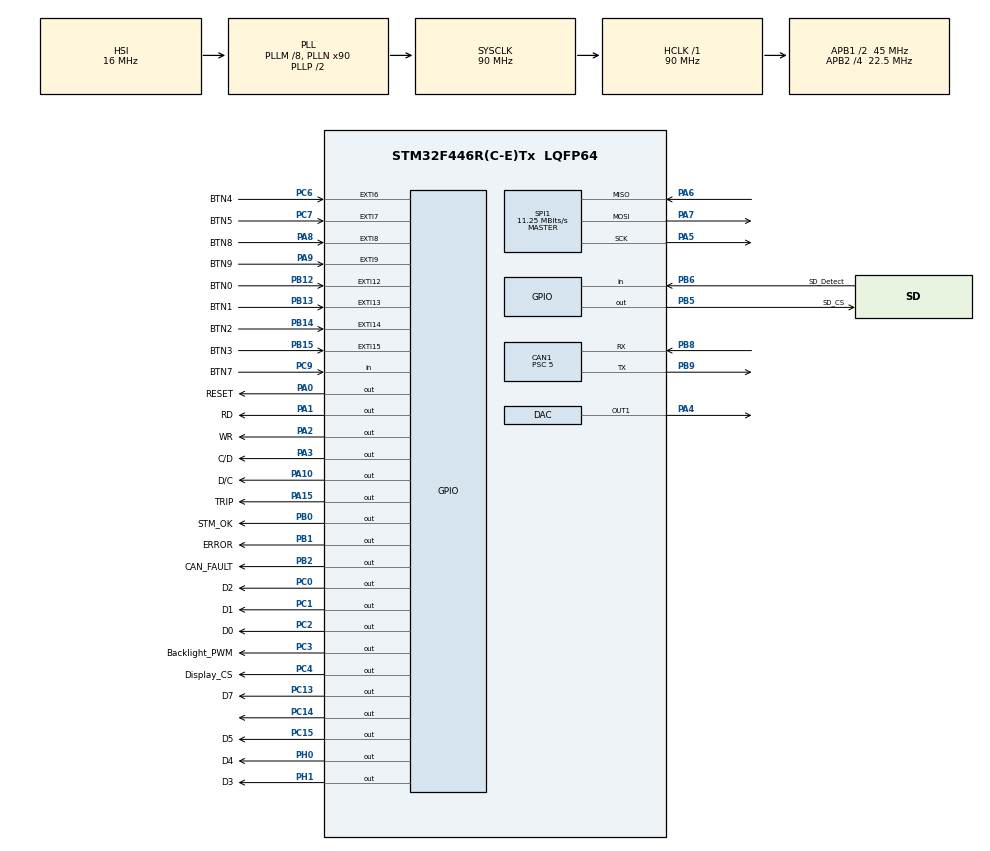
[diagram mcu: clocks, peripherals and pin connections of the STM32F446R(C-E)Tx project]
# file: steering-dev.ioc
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CAN1.BS1=CAN_BS1_15TQ
CAN1.BS2=CAN_BS2_2TQ
CAN1.CalculateBaudRate=500000
CAN1.CalculateTimeBit=2000
CAN1.CalculateTimeQuantum=111.11111111111111
CAN1.Mode=CAN_MODE_LOOPBACK
CAN1.Prescaler=5
CAN1.SJW=CAN_SJW_1TQ
DAC.DAC_Trigger=DAC_TRIGGER_T2_TRGO
Dma.DAC1.0.Direction=DMA_MEMORY_TO_PERIPH
Dma.DAC1.0.FIFOMode=DMA_FIFOMODE_DISABLE
Dma.DAC1.0.Instance=DMA1_Stream5
Dma.DAC1.0.MemDataAlignment=DMA_MDATAALIGN_WORD
Dma.DAC1.0.MemInc=DMA_MINC_ENABLE
Dma.DAC1.0.Mode=DMA_CIRCULAR
Dma.DAC1.0.PeriphDataAlignment=DMA_PDATAALIGN_WORD
Dma.DAC1.0.PeriphInc=DMA_PINC_DISABLE
Dma.DAC1.0.Priority=DMA_PRIORITY_LOW
Dma.Request0=DAC1
FATFS._FS_REENTRANT=0
FATFS._MAX_SS=4096
FREERTOS.Tasks01=defaultTask,24,128,StartDefaultTask,Default,NULL,Dynamic,NULL,NULL
FREERTOS.configTOTAL_HEAP_SIZE=3072
IWDG.Prescaler=IWDG_PRESCALER_128
IWDG.Reload=1023
Mcu.Family=STM32F4
Mcu.Name=STM32F446R(C-E)Tx
Mcu.Package=LQFP64
NVIC.CAN1_RX0_IRQn=true\:5\:0\:false\:false\:true\:true\:true\:true\:true
NVIC.CAN1_RX1_IRQn=true\:5\:0\:false\:false\:true\:true\:true\:true\:true
NVIC.DMA1_Stream5_IRQn=true\:5\:0\:false\:false\:true\:true\:false\:true\:true
NVIC.EXTI15_10_IRQn=true\:5\:0\:false\:false\:true\:true\:true\:true\:true
NVIC.EXTI9_5_IRQn=true\:5\:0\:false\:false\:true\:true\:true\:true\:true
NVIC.PriorityGroup=NVIC_PRIORITYGROUP_4
NVIC.TIM3_IRQn=true\:5\:0\:false\:false\:true\:true\:true\:true\:true
NVIC.TIM8_TRG_COM_TIM14_IRQn=true\:15\:0\:false\:false\:true\:false\:false\:true\:true
NVIC.TimeBase=TIM8_TRG_COM_TIM14_IRQn
NVIC.TimeBaseIP=TIM14
PA0-WKUP.GPIO_Label=RESET
PA0-WKUP.Signal=GPIO_Output
PA1.GPIO_Label=RD
PA1.Signal=GPIO_Output
PA10.GPIO_Label=D/C
PA10.GPIO_PuPd=GPIO_PULLUP
PA10.Signal=GPIO_Output
PA13.Mode=Serial_Wire
PA13.Signal=SYS_JTMS-SWDIO
PA14.Mode=Serial_Wire
PA14.Signal=SYS_JTCK-SWCLK
PA15.GPIO_Label=TRIP
PA15.GPIO_PuPd=GPIO_PULLDOWN
PA15.Signal=GPIO_Output
PA2.GPIO_Label=WR
PA2.Signal=GPIO_Output
PA3.GPIO_Label=C/D
PA3.Signal=GPIO_Output
PA4.Signal=COMP_DAC1_group
PA5.Mode=Full_Duplex_Master
PA5.Signal=SPI1_SCK
PA6.Mode=Full_Duplex_Master
PA6.Signal=SPI1_MISO
PA7.Mode=Full_Duplex_Master
PA7.Signal=SPI1_MOSI
PA8.GPIO_Label=BTN8
PA8.GPIO_ModeDefaultEXTI=GPIO_MODE_IT_FALLING
PA8.GPIO_PuPd=GPIO_PULLUP
PA8.Signal=GPXTI8
PA9.GPIO_Label=BTN9
PA9.GPIO_ModeDefaultEXTI=GPIO_MODE_IT_FALLING
PA9.GPIO_PuPd=GPIO_PULLUP
PA9.Signal=GPXTI9
PB0.GPIO_Label=STM_OK
PB0.Signal=GPIO_Output
PB1.GPIO_Label=ERROR
PB1.Signal=GPIO_Output
PB12.GPIO_Label=BTN0
PB12.GPIO_ModeDefaultEXTI=GPIO_MODE_IT_FALLING
PB12.GPIO_PuPd=GPIO_PULLUP
PB12.Signal=GPXTI12
PB13.GPIO_Label=BTN1
PB13.GPIO_ModeDefaultEXTI=GPIO_MODE_IT_FALLING
PB13.GPIO_PuPd=GPIO_PULLUP
PB13.Signal=GPXTI13
PB14.GPIO_Label=BTN2
PB14.GPIO_ModeDefaultEXTI=GPIO_MODE_IT_FALLING
PB14.GPIO_PuPd=GPIO_PULLUP
PB14.Signal=GPXTI14
PB15.GPIO_Label=BTN3
PB15.GPIO_ModeDefaultEXTI=GPIO_MODE_IT_FALLING
PB15.GPIO_PuPd=GPIO_PULLUP
PB15.Signal=GPXTI15
PB2.GPIO_Label=CAN_FAULT
PB2.Signal=GPIO_Output
PB5.GPIO_Label=SD_CS
PB5.Signal=GPIO_Output
PB6.GPIO_Label=SD_Detect
PB6.Signal=GPIO_Input
PB8.Mode=CAN_Activate
PB8.Signal=CAN1_RX
PB9.Mode=CAN_Activate
PB9.Signal=CAN1_TX
PC0.GPIO_Label=D2
PC0.Signal=GPIO_Output
PC1.GPIO_Label=D1
PC1.Signal=GPIO_Output
PC13.GPIO_Label=D7
PC13.Signal=GPIO_Output
PC14-OSC32_IN.Signal=GPIO_Output
PC15-OSC32_OUT.GPIO_Label=D5
PC15-OSC32_OUT.Signal=GPIO_Output
PC2.GPIO_Label=D0
PC2.Signal=GPIO_Output
PC3.GPIO_Label=Backlight_PWM
PC3.Signal=GPIO_Output
PC4.GPIO_Label=Display_CS
PC4.Signal=GPIO_Output
PC6.GPIO_Label=BTN4
PC6.GPIO_ModeDefaultEXTI=GPIO_MODE_IT_FALLING
PC6.GPIO_PuPd=GPIO_PULLUP
PC6.Signal=GPXTI6
PC7.GPIO_Label=BTN5
PC7.GPIO_ModeDefaultEXTI=GPIO_MODE_IT_FALLING
PC7.GPIO_PuPd=GPIO_PULLUP
PC7.Signal=GPXTI7
PC9.GPIO_Label=BTN7
PC9.GPIO_PuPd=GPIO_PULLUP
PC9.Signal=GPIO_Input
PH0-OSC_IN.GPIO_Label=D4
PH0-OSC_IN.Signal=GPIO_Output
PH1-OSC_OUT.GPIO_Label=D3
PH1-OSC_OUT.Signal=GPIO_Output
ProjectManager.HeapSize=0x200
ProjectManager.StackSize=0x400
ProjectManager.TargetToolchain=Makefile
RCC.AHBFreq_Value=90000000
RCC.APB1CLKDivider=RCC_HCLK_DIV2
RCC.APB1Freq_Value=45000000
RCC.APB1TimFreq_Value=90000000
RCC.APB2CLKDivider=RCC_HCLK_DIV4
RCC.APB2Freq_Value=22500000
RCC.APB2TimFreq_Value=45000000
RCC.CortexFreq_Value=90000000
RCC.HCLKFreq_Value=90000000
RCC.PLLM=8
RCC.PLLN=90
RCC.PLLQ=6
RCC.PLLSAIP=RCC_PLLSAIP_DIV4
RCC.PLLSourceVirtual=RCC_PLLSOURCE_HSI
RCC.SYSCLKFreq_VALUE=90000000
RCC.SYSCLKSource=RCC_SYSCLKSOURCE_PLLCLK
RCC.USBCLockSelection=RCC_CLK48CLKSOURCE_PLLSAIP
RCC.USBFreq_Value=48000000
RCC.VCOOutputFreq_Value=180000000
SH.COMP_DAC1_group.0=DAC_OUT1,DAC_OUT1
SPI1.BaudRatePrescaler=SPI_BAUDRATEPRESCALER_2
SPI1.CalculateBaudRate=11.25 MBits/s
SPI1.Direction=SPI_DIRECTION_2LINES
SPI1.Mode=SPI_MODE_MASTER
SPI1.VirtualType=VM_MASTER
TIM2.AutoReloadPreload=TIM_AUTORELOAD_PRELOAD_DISABLE
TIM2.Period=100
TIM2.Prescaler=31
TIM2.TIM_MasterOutputTrigger=TIM_TRGO_UPDATE
TIM2.TIM_MasterSlaveMode=TIM_MASTERSLAVEMODE_DISABLE
TIM3.Period=275
TIM3.Prescaler=4095
VP_FATFS_VS_Generic.Mode=User_defined
VP_FREERTOS_VS_CMSIS_V2.Mode=CMSIS_V2
VP_IWDG_VS_IWDG.Mode=IWDG_Activate
VP_SYS_VS_tim14.Mode=TIM14
VP_TIM2_VS_ClockSourceINT.Mode=Internal
VP_TIM3_VS_ClockSourceINT.Mode=Internal
board=custom

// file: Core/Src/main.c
/* USER CODE BEGIN Header */
/**
  ******************************************************************************
  * @file           : main.c
  * @brief          : Main program body
  ******************************************************************************
  * @attention
  *
  * Copyright (c) 2023 STMicroelectronics.
  * All rights reserved.
  *
  * This software is licensed under terms that can be found in the LICENSE file
  * in the root directory of this software component.
  * If no LICENSE file comes with this software, it is provided AS-IS.
  *
  ******************************************************************************
  */
/* USER CODE END Header */
#include "main.h"
#include "cmsis_os.h"
#include "fatfs.h"

CAN_HandleTypeDef hcan1;

DAC_HandleTypeDef hdac;
DMA_HandleTypeDef hdma_dac1;

IWDG_HandleTypeDef hiwdg;

SPI_HandleTypeDef hspi1;

TIM_HandleTypeDef htim2;
TIM_HandleTypeDef htim3;

/* Definitions for defaultTask */
osThreadId_t defaultTaskHandle;
const osThreadAttr_t defaultTask_attributes = {
  .name = "defaultTask",
  .stack_size = 128 * 4,
  .priority = (osPriority_t) osPriorityNormal,
};

void SystemClock_Config(void);
static void MX_GPIO_Init(void);
static void MX_DMA_Init(void);
static void MX_CAN1_Init(void);
static void MX_SPI1_Init(void);
static void MX_TIM2_Init(void);
static void MX_DAC_Init(void);
static void MX_TIM3_Init(void);
static void MX_IWDG_Init(void);
void StartDefaultTask(void *argument);

/* USER CODE BEGIN PFP */
void CPP_UserSetup(void);
/* USER CODE END PFP */

int main(void)
{

  /* MCU Configuration--------------------------------------------------------*/

  /* Reset of all peripherals, Initializes the Flash interface and the Systick. */
  HAL_Init();

  /* Configure the system clock */
  SystemClock_Config();

  /* USER CODE BEGIN SysInit */
   HAL_NVIC_SetPriority(TIM1_TRG_COM_TIM11_IRQn, 1U, 0U);
  __enable_irq();
  __set_BASEPRI(6);
  /* USER CODE END SysInit */

  /* Initialize all configured peripherals */
  MX_GPIO_Init();
  MX_DMA_Init();
  MX_CAN1_Init();
  MX_SPI1_Init();
  MX_FATFS_Init();
  MX_TIM2_Init();
  MX_DAC_Init();
  MX_TIM3_Init();
  MX_IWDG_Init();
  /* USER CODE BEGIN 2 */

//  HAL_DAC_Start(&hdac, DAC_CHANNEL_1);
//  HAL_DAC_Start_DMA(&hdac, DAC_CHANNEL_1, sine_vals, 100, DAC_ALIGN_12B_R);

  HAL_NVIC_SetPriority(TIM1_TRG_COM_TIM11_IRQn, 15U, 0U);
  /* USER CODE END 2 */

  /* Init scheduler */
  CPP_UserSetup();

  /* Create the thread(s) */
  /* creation of defaultTask */
  defaultTaskHandle = osThreadNew(StartDefaultTask, NULL, &defaultTask_attributes);

  /* Start scheduler */
  osKernelStart();

  /* We should never get here as control is now taken by the scheduler */

  /* Infinite loop */
  /* USER CODE BEGIN WHILE */

  while (1)
  {
	HAL_GPIO_TogglePin(STM_OK_GPIO_Port, STM_OK_Pin);
	HAL_Delay(500);

    /* USER CODE END WHILE */

  }
}

void SystemClock_Config(void)
{
  RCC_OscInitTypeDef RCC_OscInitStruct = {0};
  RCC_ClkInitTypeDef RCC_ClkInitStruct = {0};

  /** Configure the main internal regulator output voltage
  */
  __HAL_RCC_PWR_CLK_ENABLE();
  __HAL_PWR_VOLTAGESCALING_CONFIG(PWR_REGULATOR_VOLTAGE_SCALE3);

  /** Initializes the RCC Oscillators according to the specified parameters
  * in the RCC_OscInitTypeDef structure.
  */
  RCC_OscInitStruct.OscillatorType = RCC_OSCILLATORTYPE_HSI|RCC_OSCILLATORTYPE_LSI;
  RCC_OscInitStruct.HSIState = RCC_HSI_ON;
  RCC_OscInitStruct.HSICalibrationValue = RCC_HSICALIBRATION_DEFAULT;
  RCC_OscInitStruct.LSIState = RCC_LSI_ON;
  RCC_OscInitStruct.PLL.PLLState = RCC_PLL_ON;
  RCC_OscInitStruct.PLL.PLLSource = RCC_PLLSOURCE_HSI;
  RCC_OscInitStruct.PLL.PLLM = 8;
  RCC_OscInitStruct.PLL.PLLN = 90;
  RCC_OscInitStruct.PLL.PLLP = RCC_PLLP_DIV2;
  RCC_OscInitStruct.PLL.PLLQ = 6;
  RCC_OscInitStruct.PLL.PLLR = 2;
  if (HAL_RCC_OscConfig(&RCC_OscInitStruct) != HAL_OK)
  {
    Error_Handler();
  }

  /** Initializes the CPU, AHB and APB buses clocks
  */
  RCC_ClkInitStruct.ClockType = RCC_CLOCKTYPE_HCLK|RCC_CLOCKTYPE_SYSCLK
                              |RCC_CLOCKTYPE_PCLK1|RCC_CLOCKTYPE_PCLK2;
  RCC_ClkInitStruct.SYSCLKSource = RCC_SYSCLKSOURCE_PLLCLK;
  RCC_ClkInitStruct.AHBCLKDivider = RCC_SYSCLK_DIV1;
  RCC_ClkInitStruct.APB1CLKDivider = RCC_HCLK_DIV2;
  RCC_ClkInitStruct.APB2CLKDivider = RCC_HCLK_DIV4;

  if (HAL_RCC_ClockConfig(&RCC_ClkInitStruct, FLASH_LATENCY_2) != HAL_OK)
  {
    Error_Handler();
  }
}

static void MX_CAN1_Init(void)
{

  hcan1.Instance = CAN1;
  hcan1.Init.Prescaler = 5;
  hcan1.Init.Mode = CAN_MODE_LOOPBACK;
  hcan1.Init.SyncJumpWidth = CAN_SJW_1TQ;
  hcan1.Init.TimeSeg1 = CAN_BS1_15TQ;
  hcan1.Init.TimeSeg2 = CAN_BS2_2TQ;
  hcan1.Init.TimeTriggeredMode = DISABLE;
  hcan1.Init.AutoBusOff = DISABLE;
  hcan1.Init.AutoWakeUp = DISABLE;
  hcan1.Init.AutoRetransmission = DISABLE;
  hcan1.Init.ReceiveFifoLocked = DISABLE;
  hcan1.Init.TransmitFifoPriority = DISABLE;
  if (HAL_CAN_Init(&hcan1) != HAL_OK)
  {
    Error_Handler();
  }

}

static void MX_DAC_Init(void)
{

  DAC_ChannelConfTypeDef sConfig = {0};

  /** DAC Initialization
  */
  hdac.Instance = DAC;
  if (HAL_DAC_Init(&hdac) != HAL_OK)
  {
    Error_Handler();
  }

  /** DAC channel OUT1 config
  */
  sConfig.DAC_Trigger = DAC_TRIGGER_T2_TRGO;
  sConfig.DAC_OutputBuffer = DAC_OUTPUTBUFFER_ENABLE;
  if (HAL_DAC_ConfigChannel(&hdac, &sConfig, DAC_CHANNEL_1) != HAL_OK)
  {
    Error_Handler();
  }

}

static void MX_IWDG_Init(void)
{

  hiwdg.Instance = IWDG;
  hiwdg.Init.Prescaler = IWDG_PRESCALER_128;
  hiwdg.Init.Reload = 1023;
  if (HAL_IWDG_Init(&hiwdg) != HAL_OK)
  {
    Error_Handler();
  }

}

static void MX_SPI1_Init(void)
{

  /* SPI1 parameter configuration*/
  hspi1.Instance = SPI1;
  hspi1.Init.Mode = SPI_MODE_MASTER;
  hspi1.Init.Direction = SPI_DIRECTION_2LINES;
  hspi1.Init.DataSize = SPI_DATASIZE_8BIT;
  hspi1.Init.CLKPolarity = SPI_POLARITY_LOW;
  hspi1.Init.CLKPhase = SPI_PHASE_1EDGE;
  hspi1.Init.NSS = SPI_NSS_SOFT;
  hspi1.Init.BaudRatePrescaler = SPI_BAUDRATEPRESCALER_2;
  hspi1.Init.FirstBit = SPI_FIRSTBIT_MSB;
  hspi1.Init.TIMode = SPI_TIMODE_DISABLE;
  hspi1.Init.CRCCalculation = SPI_CRCCALCULATION_DISABLE;
  hspi1.Init.CRCPolynomial = 10;
  if (HAL_SPI_Init(&hspi1) != HAL_OK)
  {
    Error_Handler();
  }

}

static void MX_TIM2_Init(void)
{

  TIM_ClockConfigTypeDef sClockSourceConfig = {0};
  TIM_MasterConfigTypeDef sMasterConfig = {0};

  htim2.Instance = TIM2;
  htim2.Init.Prescaler = 31;
  htim2.Init.CounterMode = TIM_COUNTERMODE_UP;
  htim2.Init.Period = 100;
  htim2.Init.ClockDivision = TIM_CLOCKDIVISION_DIV1;
  htim2.Init.AutoReloadPreload = TIM_AUTORELOAD_PRELOAD_DISABLE;
  if (HAL_TIM_Base_Init(&htim2) != HAL_OK)
  {
    Error_Handler();
  }
  sClockSourceConfig.ClockSource = TIM_CLOCKSOURCE_INTERNAL;
  if (HAL_TIM_ConfigClockSource(&htim2, &sClockSourceConfig) != HAL_OK)
  {
    Error_Handler();
  }
  sMasterConfig.MasterOutputTrigger = TIM_TRGO_UPDATE;
  sMasterConfig.MasterSlaveMode = TIM_MASTERSLAVEMODE_DISABLE;
  if (HAL_TIMEx_MasterConfigSynchronization(&htim2, &sMasterConfig) != HAL_OK)
  {
    Error_Handler();
  }

}

static void MX_TIM3_Init(void)
{

  TIM_ClockConfigTypeDef sClockSourceConfig = {0};
  TIM_MasterConfigTypeDef sMasterConfig = {0};

  htim3.Instance = TIM3;
  htim3.Init.Prescaler = 4095;
  htim3.Init.CounterMode = TIM_COUNTERMODE_UP;
  htim3.Init.Period = 275;
  htim3.Init.ClockDivision = TIM_CLOCKDIVISION_DIV1;
  htim3.Init.AutoReloadPreload = TIM_AUTORELOAD_PRELOAD_DISABLE;
  if (HAL_TIM_Base_Init(&htim3) != HAL_OK)
  {
    Error_Handler();
  }
  sClockSourceConfig.ClockSource = TIM_CLOCKSOURCE_INTERNAL;
  if (HAL_TIM_ConfigClockSource(&htim3, &sClockSourceConfig) != HAL_OK)
  {
    Error_Handler();
  }
  sMasterConfig.MasterOutputTrigger = TIM_TRGO_RESET;
  sMasterConfig.MasterSlaveMode = TIM_MASTERSLAVEMODE_DISABLE;
  if (HAL_TIMEx_MasterConfigSynchronization(&htim3, &sMasterConfig) != HAL_OK)
  {
    Error_Handler();
  }

}

static void MX_DMA_Init(void)
{

  /* DMA controller clock enable */
  __HAL_RCC_DMA1_CLK_ENABLE();

  /* DMA interrupt init */
  /* DMA1_Stream5_IRQn interrupt configuration */
  HAL_NVIC_SetPriority(DMA1_Stream5_IRQn, 5, 0);
  HAL_NVIC_EnableIRQ(DMA1_Stream5_IRQn);

}

static void MX_GPIO_Init(void)
{
  GPIO_InitTypeDef GPIO_InitStruct = {0};

  /* GPIO Ports Clock Enable */
  __HAL_RCC_GPIOC_CLK_ENABLE();
  __HAL_RCC_GPIOH_CLK_ENABLE();
  __HAL_RCC_GPIOA_CLK_ENABLE();
  __HAL_RCC_GPIOB_CLK_ENABLE();

  /*Configure GPIO pin Output Level */
  HAL_GPIO_WritePin(GPIOC, D7_Pin|GPIO_PIN_14|D5_Pin|D2_Pin
                          |D1_Pin|D0_Pin|Backlight_PWM_Pin|Display_CS_Pin, GPIO_PIN_RESET);

  /*Configure GPIO pin Output Level */
  HAL_GPIO_WritePin(GPIOH, D4_Pin|D3_Pin, GPIO_PIN_RESET);

  /*Configure GPIO pin Output Level */
  HAL_GPIO_WritePin(GPIOA, RESET_Pin|RD_Pin|WR_Pin|C_D_Pin
                          |D_C_Pin|TRIP_Pin, GPIO_PIN_RESET);

  /*Configure GPIO pin Output Level */
  HAL_GPIO_WritePin(GPIOB, STM_OK_Pin|ERROR_Pin|CAN_FAULT_Pin|SD_CS_Pin, GPIO_PIN_RESET);

  /*Configure GPIO pins : D7_Pin PC14 D5_Pin D2_Pin
                           D1_Pin D0_Pin Backlight_PWM_Pin Display_CS_Pin */
  GPIO_InitStruct.Pin = D7_Pin|GPIO_PIN_14|D5_Pin|D2_Pin
                          |D1_Pin|D0_Pin|Backlight_PWM_Pin|Display_CS_Pin;
  GPIO_InitStruct.Mode = GPIO_MODE_OUTPUT_PP;
  GPIO_InitStruct.Pull = GPIO_NOPULL;
  GPIO_InitStruct.Speed = GPIO_SPEED_FREQ_LOW;
  HAL_GPIO_Init(GPIOC, &GPIO_InitStruct);

  /*Configure GPIO pins : D4_Pin D3_Pin */
  GPIO_InitStruct.Pin = D4_Pin|D3_Pin;
  GPIO_InitStruct.Mode = GPIO_MODE_OUTPUT_PP;
  GPIO_InitStruct.Pull = GPIO_NOPULL;
  GPIO_InitStruct.Speed = GPIO_SPEED_FREQ_LOW;
  HAL_GPIO_Init(GPIOH, &GPIO_InitStruct);

  /*Configure GPIO pins : RESET_Pin RD_Pin WR_Pin C_D_Pin */
  GPIO_InitStruct.Pin = RESET_Pin|RD_Pin|WR_Pin|C_D_Pin;
  GPIO_InitStruct.Mode = GPIO_MODE_OUTPUT_PP;
  GPIO_InitStruct.Pull = GPIO_NOPULL;
  GPIO_InitStruct.Speed = GPIO_SPEED_FREQ_LOW;
  HAL_GPIO_Init(GPIOA, &GPIO_InitStruct);

  /*Configure GPIO pins : STM_OK_Pin ERROR_Pin CAN_FAULT_Pin SD_CS_Pin */
  GPIO_InitStruct.Pin = STM_OK_Pin|ERROR_Pin|CAN_FAULT_Pin|SD_CS_Pin;
  GPIO_InitStruct.Mode = GPIO_MODE_OUTPUT_PP;
  GPIO_InitStruct.Pull = GPIO_NOPULL;
  GPIO_InitStruct.Speed = GPIO_SPEED_FREQ_LOW;
  HAL_GPIO_Init(GPIOB, &GPIO_InitStruct);

  /*Configure GPIO pins : BTN0_Pin BTN2_Pin BTN3_Pin */
  GPIO_InitStruct.Pin = BTN0_Pin|BTN2_Pin|BTN3_Pin;
  GPIO_InitStruct.Mode = GPIO_MODE_IT_FALLING;
  GPIO_InitStruct.Pull = GPIO_PULLUP;
  HAL_GPIO_Init(GPIOB, &GPIO_InitStruct);

  /*Configure GPIO pin : BTN1_Pin */
  GPIO_InitStruct.Pin = BTN1_Pin;
  GPIO_InitStruct.Mode = GPIO_MODE_IT_RISING;
  GPIO_InitStruct.Pull = GPIO_PULLUP;
  HAL_GPIO_Init(BTN1_GPIO_Port, &GPIO_InitStruct);

  /*Configure GPIO pins : BTN4_Pin BTN5_Pin BTN6_Pin */
  GPIO_InitStruct.Pin = BTN4_Pin|BTN5_Pin|BTN6_Pin;
  GPIO_InitStruct.Mode = GPIO_MODE_IT_FALLING;
  GPIO_InitStruct.Pull = GPIO_PULLUP;
  HAL_GPIO_Init(GPIOC, &GPIO_InitStruct);

  /*Configure GPIO pin : BTN7_Pin */
  GPIO_InitStruct.Pin = BTN7_Pin;
  GPIO_InitStruct.Mode = GPIO_MODE_INPUT;
  GPIO_InitStruct.Pull = GPIO_PULLUP;
  HAL_GPIO_Init(BTN7_GPIO_Port, &GPIO_InitStruct);

  /*Configure GPIO pin : BTN8_Pin */
  GPIO_InitStruct.Pin = BTN8_Pin;
  GPIO_InitStruct.Mode = GPIO_MODE_INPUT;
  GPIO_InitStruct.Pull = GPIO_PULLUP;
  HAL_GPIO_Init(BTN8_GPIO_Port, &GPIO_InitStruct);

  /*Configure GPIO pin : BTN9_Pin */
  GPIO_InitStruct.Pin = BTN9_Pin;
  GPIO_InitStruct.Mode = GPIO_MODE_IT_FALLING;
  GPIO_InitStruct.Pull = GPIO_PULLUP;
  HAL_GPIO_Init(BTN9_GPIO_Port, &GPIO_InitStruct);

  /*Configure GPIO pin : D_C_Pin */
  GPIO_InitStruct.Pin = D_C_Pin;
  GPIO_InitStruct.Mode = GPIO_MODE_OUTPUT_PP;
  GPIO_InitStruct.Pull = GPIO_PULLUP;
  GPIO_InitStruct.Speed = GPIO_SPEED_FREQ_LOW;
  HAL_GPIO_Init(D_C_GPIO_Port, &GPIO_InitStruct);

  /*Configure GPIO pin : TRIP_Pin */
  GPIO_InitStruct.Pin = TRIP_Pin;
  GPIO_InitStruct.Mode = GPIO_MODE_OUTPUT_PP;
  GPIO_InitStruct.Pull = GPIO_PULLDOWN;
  GPIO_InitStruct.Speed = GPIO_SPEED_FREQ_LOW;
  HAL_GPIO_Init(TRIP_GPIO_Port, &GPIO_InitStruct);

  /*Configure GPIO pin : SD_Detect_Pin */
  GPIO_InitStruct.Pin = SD_Detect_Pin;
  GPIO_InitStruct.Mode = GPIO_MODE_INPUT;
  GPIO_InitStruct.Pull = GPIO_NOPULL;
  HAL_GPIO_Init(SD_Detect_GPIO_Port, &GPIO_InitStruct);

  /* EXTI interrupt init*/
  HAL_NVIC_SetPriority(EXTI9_5_IRQn, 5, 0);
  HAL_NVIC_EnableIRQ(EXTI9_5_IRQn);

  HAL_NVIC_SetPriority(EXTI15_10_IRQn, 5, 0);
  HAL_NVIC_EnableIRQ(EXTI15_10_IRQn);

}

void StartDefaultTask(void *argument)
{
  /* USER CODE BEGIN 5 */
//   /* Infinite loop */
//   for(;;)
//   {
// 	HAL_GPIO_TogglePin(STM_OK_GPIO_Port, STM_OK_Pin);
// 	// HAL_GPIO_TogglePin(DAC_OUT1_GPIO_Port, DAC_OUT1_Pin);
// 	osDelay(500);
//   }
  /* USER CODE END 5 */
}

void HAL_TIM_PeriodElapsedCallback(TIM_HandleTypeDef *htim)
{
  if (htim->Instance == TIM14) {
    HAL_IncTick();
  }
}

void Error_Handler(void)
{
  /* USER CODE BEGIN Error_Handler_Debug */
  /* User can add his own implementation to report the HAL error return state */
  __disable_irq();
  while (1)
  {
	  HAL_GPIO_WritePin(STM_OK_GPIO_Port, STM_OK_Pin, GPIO_PIN_RESET);
	  HAL_GPIO_WritePin(ERROR_GPIO_Port, ERROR_Pin, GPIO_PIN_SET);
  }
  /* USER CODE END Error_Handler_Debug */
}
